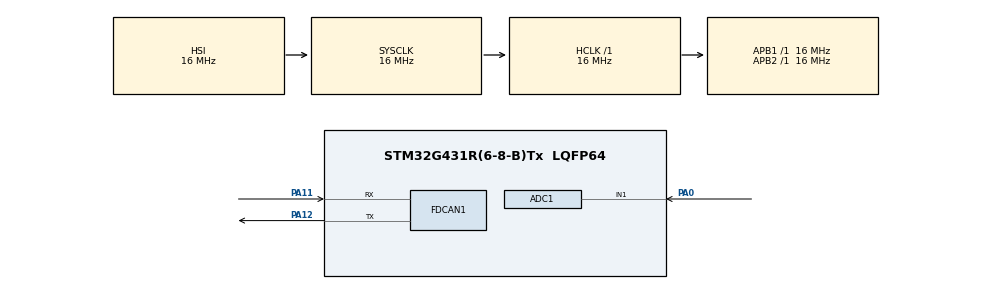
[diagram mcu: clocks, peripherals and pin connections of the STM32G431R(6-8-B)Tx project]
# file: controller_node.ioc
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ADC1.Channel-0\#ChannelRegularConversion=ADC_CHANNEL_1
ADC1.NbrOfConversionFlag=1
ADC1.OffsetNumber-0\#ChannelRegularConversion=ADC_OFFSET_NONE
ADC1.Rank-0\#ChannelRegularConversion=1
ADC1.SamplingTime-0\#ChannelRegularConversion=ADC_SAMPLETIME_2CYCLES_5
ADC1.master=1
FDCAN1.CalculateBaudRateNominal=500000
FDCAN1.CalculateTimeBitNominal=2000
FDCAN1.CalculateTimeQuantumNominal=125.0
FDCAN1.NominalPrescaler=2
FDCAN1.NominalSyncJumpWidth=2
FDCAN1.NominalTimeSeg1=13
FDCAN1.NominalTimeSeg2=2
Mcu.Family=STM32G4
Mcu.Name=STM32G431R(6-8-B)Tx
Mcu.Package=LQFP64
NVIC.PriorityGroup=NVIC_PRIORITYGROUP_4
PA0.Mode=IN1-Single-Ended
PA0.Signal=ADC1_IN1
PA11.Mode=FDCAN_Activate
PA11.Signal=FDCAN1_RX
PA12.Mode=FDCAN_Activate
PA12.Signal=FDCAN1_TX
ProjectManager.HeapSize=0x200
ProjectManager.StackSize=0x400
ProjectManager.TargetToolchain=STM32CubeIDE
RCC.AHBFreq_Value=16000000
RCC.APB1Freq_Value=16000000
RCC.APB1TimFreq_Value=16000000
RCC.APB2Freq_Value=16000000
RCC.APB2TimFreq_Value=16000000
RCC.CortexFreq_Value=16000000
RCC.EXTERNAL_CLOCK_VALUE=12288000
RCC.HCLKFreq_Value=16000000
RCC.HSE_VALUE=8000000
RCC.HSI48_VALUE=48000000
RCC.HSI_VALUE=16000000
RCC.LSE_VALUE=32768
RCC.SYSCLKFreq_VALUE=16000000
RCC.USBFreq_Value=64000000
RCC.VCOOutputFreq_Value=128000000
VP_SYS_VS_DBSignals.Mode=DisableDeadBatterySignals
board=custom

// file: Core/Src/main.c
/* USER CODE BEGIN Header */
/**
  ******************************************************************************
  * @file           : main.c
  * @brief          : Main program body
  ******************************************************************************
  * @attention
  *
  * Copyright (c) 2026 STMicroelectronics.
  * All rights reserved.
  *
  * This software is licensed under terms that can be found in the LICENSE file
  * in the root directory of this software component.
  * If no LICENSE file comes with this software, it is provided AS-IS.
  *
  ******************************************************************************
  */
/* USER CODE END Header */
#include "main.h"

ADC_HandleTypeDef hadc1;

FDCAN_HandleTypeDef hfdcan1;

/* USER CODE BEGIN PV */

volatile uint16_t adc_value = 0;

volatile uint16_t target_rpm = 0;

uint8_t txData[4] = {0, 0, 0, 0};

/* USER CODE END PV */

void SystemClock_Config(void);
static void MX_GPIO_Init(void);
static void MX_ADC1_Init(void);
static void MX_FDCAN1_Init(void);

int main(void)
{

  /* MCU Configuration--------------------------------------------------------*/

  /* Reset of all peripherals, Initializes the Flash interface and the Systick. */
  HAL_Init();

  /* Configure the system clock */
  SystemClock_Config();

  /* Initialize all configured peripherals */
  MX_GPIO_Init();
  MX_ADC1_Init();
  MX_FDCAN1_Init();
  /* USER CODE BEGIN 2 */

  HAL_FDCAN_Start(&hfdcan1);

  FDCAN_TxHeaderTypeDef txHeader;
//  uint8_t txData[4] = {0, 0, 0, 0};

  txHeader.Identifier = 0x123;
  txHeader.IdType = FDCAN_STANDARD_ID;
  txHeader.TxFrameType = FDCAN_DATA_FRAME;
  txHeader.DataLength = FDCAN_DLC_BYTES_4;
  txHeader.ErrorStateIndicator = FDCAN_ESI_ACTIVE;
  txHeader.BitRateSwitch = FDCAN_BRS_OFF;
  txHeader.FDFormat = FDCAN_CLASSIC_CAN;
  txHeader.TxEventFifoControl = FDCAN_NO_TX_EVENTS;
  txHeader.MessageMarker = 0;

  /* USER CODE END 2 */

  /* Infinite loop */
  while (1)
  {

	HAL_ADC_Start(&hadc1);
	HAL_ADC_PollForConversion(&hadc1, HAL_MAX_DELAY);
	adc_value = HAL_ADC_GetValue(&hadc1);

	target_rpm = 60.0f + ((float)adc_value / 4095.0f) * 220.0f;

	txData[0] = (target_rpm >> 8) & 0xFF;
	txData[1] = target_rpm & 0xFF;

	HAL_FDCAN_AddMessageToTxFifoQ(&hfdcan1, &txHeader, txData);

	HAL_ADC_Stop(&hadc1);

	HAL_Delay(50);

  }
}

void SystemClock_Config(void)
{
  RCC_OscInitTypeDef RCC_OscInitStruct = {0};
  RCC_ClkInitTypeDef RCC_ClkInitStruct = {0};

  /** Configure the main internal regulator output voltage
  */
  HAL_PWREx_ControlVoltageScaling(PWR_REGULATOR_VOLTAGE_SCALE1);

  /** Initializes the RCC Oscillators according to the specified parameters
  * in the RCC_OscInitTypeDef structure.
  */
  RCC_OscInitStruct.OscillatorType = RCC_OSCILLATORTYPE_HSI;
  RCC_OscInitStruct.HSIState = RCC_HSI_ON;
  RCC_OscInitStruct.HSICalibrationValue = RCC_HSICALIBRATION_DEFAULT;
  RCC_OscInitStruct.PLL.PLLState = RCC_PLL_NONE;
  if (HAL_RCC_OscConfig(&RCC_OscInitStruct) != HAL_OK)
  {
    Error_Handler();
  }

  /** Initializes the CPU, AHB and APB buses clocks
  */
  RCC_ClkInitStruct.ClockType = RCC_CLOCKTYPE_HCLK|RCC_CLOCKTYPE_SYSCLK
                              |RCC_CLOCKTYPE_PCLK1|RCC_CLOCKTYPE_PCLK2;
  RCC_ClkInitStruct.SYSCLKSource = RCC_SYSCLKSOURCE_HSI;
  RCC_ClkInitStruct.AHBCLKDivider = RCC_SYSCLK_DIV1;
  RCC_ClkInitStruct.APB1CLKDivider = RCC_HCLK_DIV1;
  RCC_ClkInitStruct.APB2CLKDivider = RCC_HCLK_DIV1;

  if (HAL_RCC_ClockConfig(&RCC_ClkInitStruct, FLASH_LATENCY_0) != HAL_OK)
  {
    Error_Handler();
  }
}

static void MX_ADC1_Init(void)
{

  ADC_MultiModeTypeDef multimode = {0};
  ADC_ChannelConfTypeDef sConfig = {0};

  /** Common config
  */
  hadc1.Instance = ADC1;
  hadc1.Init.ClockPrescaler = ADC_CLOCK_SYNC_PCLK_DIV2;
  hadc1.Init.Resolution = ADC_RESOLUTION_12B;
  hadc1.Init.DataAlign = ADC_DATAALIGN_RIGHT;
  hadc1.Init.GainCompensation = 0;
  hadc1.Init.ScanConvMode = ADC_SCAN_DISABLE;
  hadc1.Init.EOCSelection = ADC_EOC_SINGLE_CONV;
  hadc1.Init.LowPowerAutoWait = DISABLE;
  hadc1.Init.ContinuousConvMode = DISABLE;
  hadc1.Init.NbrOfConversion = 1;
  hadc1.Init.DiscontinuousConvMode = DISABLE;
  hadc1.Init.ExternalTrigConv = ADC_SOFTWARE_START;
  hadc1.Init.ExternalTrigConvEdge = ADC_EXTERNALTRIGCONVEDGE_NONE;
  hadc1.Init.DMAContinuousRequests = DISABLE;
  hadc1.Init.Overrun = ADC_OVR_DATA_PRESERVED;
  hadc1.Init.OversamplingMode = DISABLE;
  if (HAL_ADC_Init(&hadc1) != HAL_OK)
  {
    Error_Handler();
  }

  /** Configure the ADC multi-mode
  */
  multimode.Mode = ADC_MODE_INDEPENDENT;
  if (HAL_ADCEx_MultiModeConfigChannel(&hadc1, &multimode) != HAL_OK)
  {
    Error_Handler();
  }

  /** Configure Regular Channel
  */
  sConfig.Channel = ADC_CHANNEL_1;
  sConfig.Rank = ADC_REGULAR_RANK_1;
  sConfig.SamplingTime = ADC_SAMPLETIME_2CYCLES_5;
  sConfig.SingleDiff = ADC_SINGLE_ENDED;
  sConfig.OffsetNumber = ADC_OFFSET_NONE;
  sConfig.Offset = 0;
  if (HAL_ADC_ConfigChannel(&hadc1, &sConfig) != HAL_OK)
  {
    Error_Handler();
  }

}

static void MX_FDCAN1_Init(void)
{

  hfdcan1.Instance = FDCAN1;
  hfdcan1.Init.ClockDivider = FDCAN_CLOCK_DIV1;
  hfdcan1.Init.FrameFormat = FDCAN_FRAME_CLASSIC;
  hfdcan1.Init.Mode = FDCAN_MODE_NORMAL;
  hfdcan1.Init.AutoRetransmission = DISABLE;
  hfdcan1.Init.TransmitPause = DISABLE;
  hfdcan1.Init.ProtocolException = DISABLE;
  hfdcan1.Init.NominalPrescaler = 2;
  hfdcan1.Init.NominalSyncJumpWidth = 2;
  hfdcan1.Init.NominalTimeSeg1 = 13;
  hfdcan1.Init.NominalTimeSeg2 = 2;
  hfdcan1.Init.DataPrescaler = 1;
  hfdcan1.Init.DataSyncJumpWidth = 1;
  hfdcan1.Init.DataTimeSeg1 = 1;
  hfdcan1.Init.DataTimeSeg2 = 1;
  hfdcan1.Init.StdFiltersNbr = 0;
  hfdcan1.Init.ExtFiltersNbr = 0;
  hfdcan1.Init.TxFifoQueueMode = FDCAN_TX_FIFO_OPERATION;
  if (HAL_FDCAN_Init(&hfdcan1) != HAL_OK)
  {
    Error_Handler();
  }

}

static void MX_GPIO_Init(void)
{

  /* GPIO Ports Clock Enable */
  __HAL_RCC_GPIOA_CLK_ENABLE();

}

void Error_Handler(void)
{
  __disable_irq();
  while (1)
  {
  }
}
